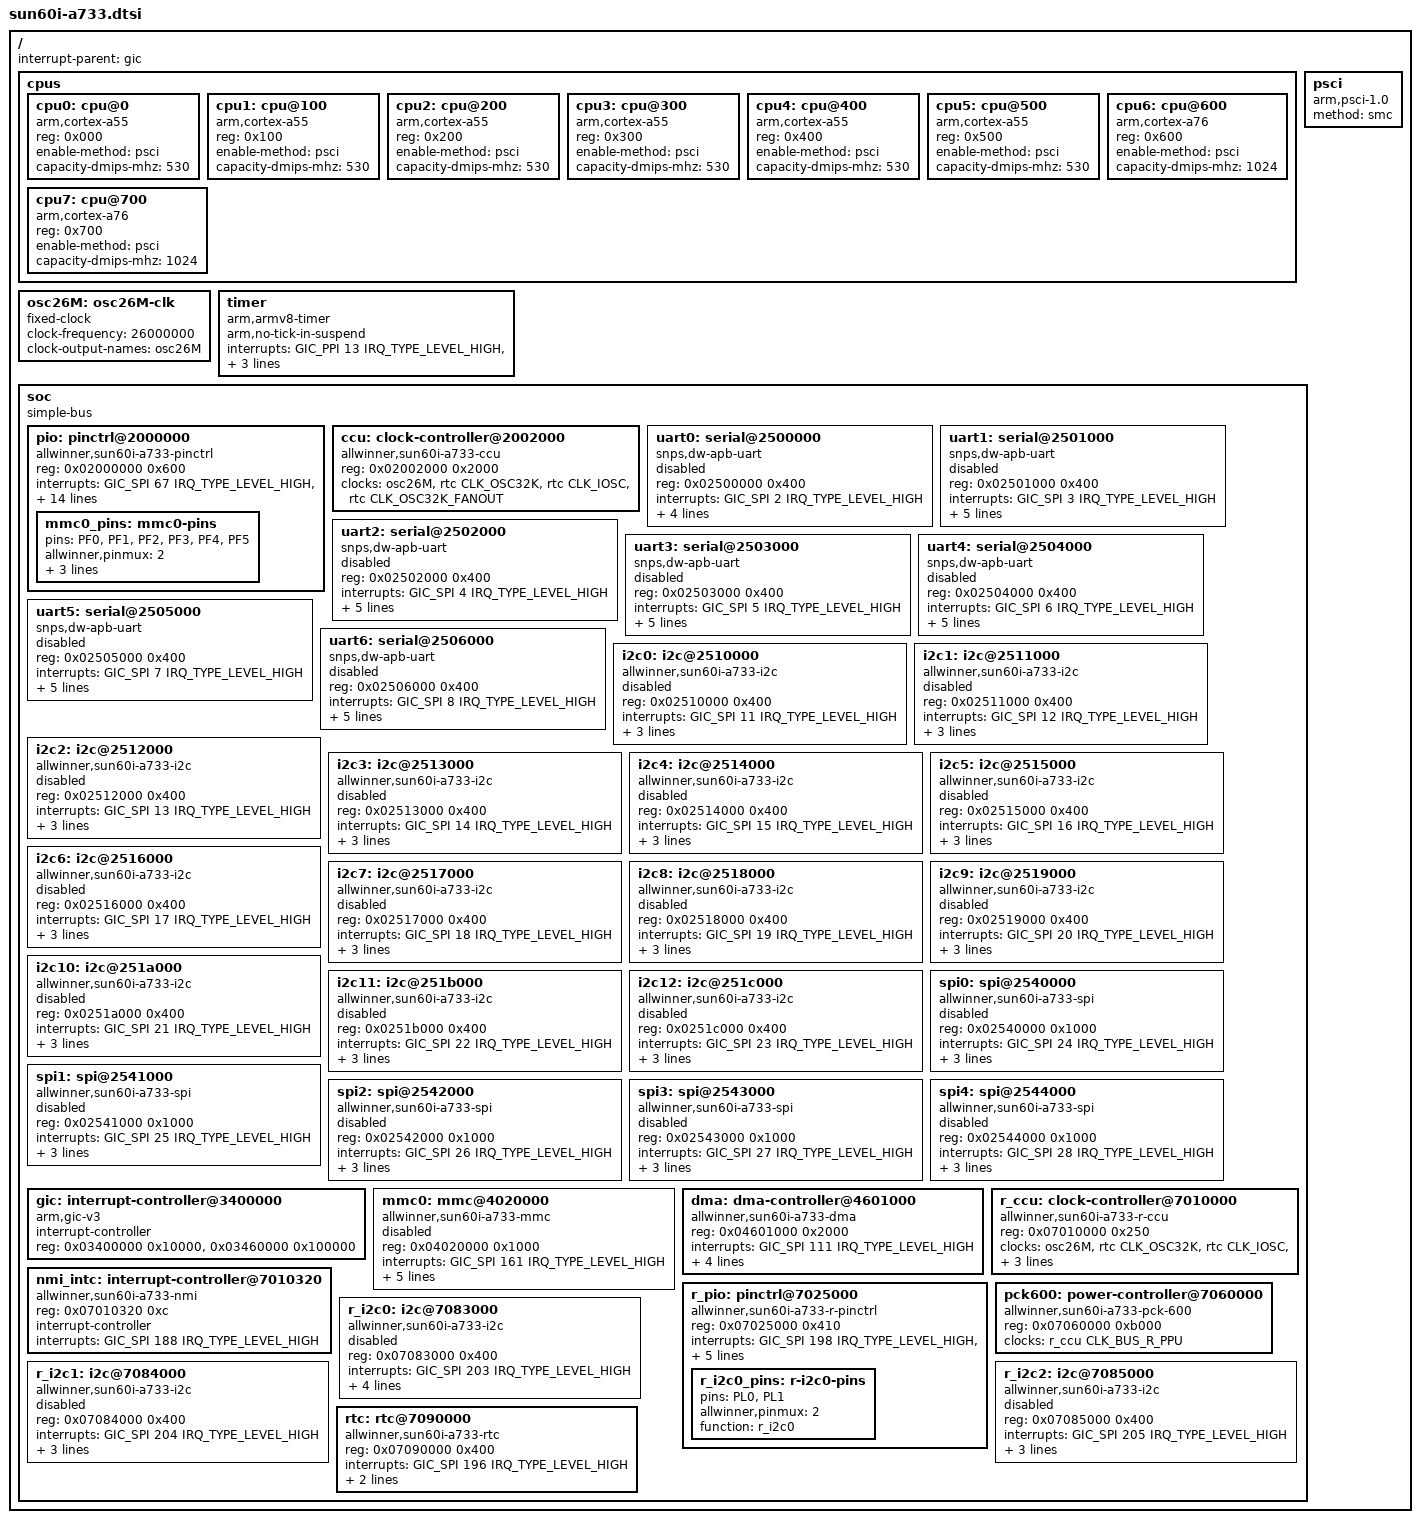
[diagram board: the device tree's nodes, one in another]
// SPDX-License-Identifier: (GPL-2.0-only OR MIT)

#include <dt-bindings/interrupt-controller/arm-gic.h>
#include <dt-bindings/clock/sun6i-rtc.h>
#include <dt-bindings/clock/sun60i-a733-ccu.h>
#include <dt-bindings/clock/sun60i-a733-r-ccu.h>
#include <dt-bindings/power/allwinner,sun60i-a733-pck-600.h>
#include <dt-bindings/reset/sun60i-a733-ccu.h>
#include <dt-bindings/reset/sun60i-a733-r-ccu.h>

/ {
	interrupt-parent = <&gic>;
	#address-cells = <2>;
	#size-cells = <2>;

	cpus {
		#address-cells = <1>;
		#size-cells = <0>;

		cpu0: cpu@0 {
			compatible = "arm,cortex-a55";
			device_type = "cpu";
			reg = <0x000>;
			enable-method = "psci";
			capacity-dmips-mhz = <530>;
		};

		cpu1: cpu@100 {
			compatible = "arm,cortex-a55";
			device_type = "cpu";
			reg = <0x100>;
			enable-method = "psci";
			capacity-dmips-mhz = <530>;
		};

		cpu2: cpu@200 {
			compatible = "arm,cortex-a55";
			device_type = "cpu";
			reg = <0x200>;
			enable-method = "psci";
			capacity-dmips-mhz = <530>;
		};

		cpu3: cpu@300 {
			compatible = "arm,cortex-a55";
			device_type = "cpu";
			reg = <0x300>;
			enable-method = "psci";
			capacity-dmips-mhz = <530>;
		};

		cpu4: cpu@400 {
			compatible = "arm,cortex-a55";
			device_type = "cpu";
			reg = <0x400>;
			enable-method = "psci";
			capacity-dmips-mhz = <530>;
		};

		cpu5: cpu@500 {
			compatible = "arm,cortex-a55";
			device_type = "cpu";
			reg = <0x500>;
			enable-method = "psci";
			capacity-dmips-mhz = <530>;
		};

		cpu6: cpu@600 {
			compatible = "arm,cortex-a76";
			device_type = "cpu";
			reg = <0x600>;
			enable-method = "psci";
			capacity-dmips-mhz = <1024>;
		};

		cpu7: cpu@700 {
			compatible = "arm,cortex-a76";
			device_type = "cpu";
			reg = <0x700>;
			enable-method = "psci";
			capacity-dmips-mhz = <1024>;
		};
	};

	osc26M: osc26M-clk {
		#clock-cells = <0>;
		compatible = "fixed-clock";
		clock-frequency = <26000000>;
		clock-output-names = "osc26M";
	};

	psci {
		compatible = "arm,psci-1.0", "arm,psci-0.2";
		method = "smc";
	};

	timer {
		compatible = "arm,armv8-timer";
		arm,no-tick-in-suspend;
		interrupts = <GIC_PPI 13 IRQ_TYPE_LEVEL_HIGH>,
			     <GIC_PPI 14 IRQ_TYPE_LEVEL_HIGH>,
			     <GIC_PPI 11 IRQ_TYPE_LEVEL_HIGH>,
			     <GIC_PPI 10 IRQ_TYPE_LEVEL_HIGH>;
	};

	soc {
		compatible = "simple-bus";
		#address-cells = <1>;
		#size-cells = <1>;
		ranges = <0x0 0x0 0x0 0x40000000>;

		pio: pinctrl@2000000 {
			compatible = "allwinner,sun60i-a733-pinctrl";
			reg = <0x02000000 0x600>;
			interrupts = <GIC_SPI 67 IRQ_TYPE_LEVEL_HIGH>,
				     <GIC_SPI 69 IRQ_TYPE_LEVEL_HIGH>,
				     <GIC_SPI 71 IRQ_TYPE_LEVEL_HIGH>,
				     <GIC_SPI 73 IRQ_TYPE_LEVEL_HIGH>,
				     <GIC_SPI 75 IRQ_TYPE_LEVEL_HIGH>,
				     <GIC_SPI 77 IRQ_TYPE_LEVEL_HIGH>,
				     <GIC_SPI 79 IRQ_TYPE_LEVEL_HIGH>,
				     <GIC_SPI 81 IRQ_TYPE_LEVEL_HIGH>,
				     <GIC_SPI 83 IRQ_TYPE_LEVEL_HIGH>,
				     <GIC_SPI 85 IRQ_TYPE_LEVEL_HIGH>,
				     <GIC_SPI 87 IRQ_TYPE_LEVEL_HIGH>;
			clocks = <&ccu CLK_APB1>, <&ccu CLK_SYS_24M>,
				 <&rtc CLK_OSC32K>;
			clock-names = "apb", "hosc", "losc";
			gpio-controller;
			#gpio-cells = <3>;
			interrupt-controller;
			#interrupt-cells = <3>;

			mmc0_pins: mmc0-pins {
				pins = "PF0", "PF1", "PF2",
				       "PF3", "PF4", "PF5";
				allwinner,pinmux = <2>;
				function = "mmc0";
				drive-strength = <30>;
				bias-pull-up;
			};

		};

		ccu: clock-controller@2002000 {
			compatible = "allwinner,sun60i-a733-ccu";
			reg = <0x02002000 0x2000>;
			clocks = <&osc26M>, <&rtc CLK_OSC32K>,
				 <&rtc CLK_IOSC>, <&rtc CLK_OSC32K_FANOUT>;
			clock-names = "hosc", "losc",
				      "iosc", "losc-fanout";
			#clock-cells = <1>;
			#reset-cells = <1>;
		};

		uart0: serial@2500000 {
			compatible = "snps,dw-apb-uart";
			reg = <0x02500000 0x400>;
			interrupts = <GIC_SPI 2 IRQ_TYPE_LEVEL_HIGH>;
			reg-shift = <2>;
			reg-io-width = <4>;
			clocks = <&ccu CLK_BUS_UART0>;
			resets = <&ccu RST_BUS_UART0>;
			status = "disabled";
		};

		uart1: serial@2501000 {
			compatible = "snps,dw-apb-uart";
			reg = <0x02501000 0x400>;
			interrupts = <GIC_SPI 3 IRQ_TYPE_LEVEL_HIGH>;
			reg-shift = <2>;
			reg-io-width = <4>;
			clocks = <&ccu CLK_BUS_UART1>;
			resets = <&ccu RST_BUS_UART1>;
			dmas = <&dma 15>, <&dma 15>;
			dma-names = "tx", "rx";
			status = "disabled";
		};

		uart2: serial@2502000 {
			compatible = "snps,dw-apb-uart";
			reg = <0x02502000 0x400>;
			interrupts = <GIC_SPI 4 IRQ_TYPE_LEVEL_HIGH>;
			reg-shift = <2>;
			reg-io-width = <4>;
			clocks = <&ccu CLK_BUS_UART2>;
			resets = <&ccu RST_BUS_UART2>;
			dmas = <&dma 16>, <&dma 16>;
			dma-names = "tx", "rx";
			status = "disabled";
		};

		uart3: serial@2503000 {
			compatible = "snps,dw-apb-uart";
			reg = <0x02503000 0x400>;
			interrupts = <GIC_SPI 5 IRQ_TYPE_LEVEL_HIGH>;
			reg-shift = <2>;
			reg-io-width = <4>;
			clocks = <&ccu CLK_BUS_UART3>;
			resets = <&ccu RST_BUS_UART3>;
			dmas = <&dma 17>, <&dma 17>;
			dma-names = "tx", "rx";
			status = "disabled";
		};

		uart4: serial@2504000 {
			compatible = "snps,dw-apb-uart";
			reg = <0x02504000 0x400>;
			interrupts = <GIC_SPI 6 IRQ_TYPE_LEVEL_HIGH>;
			reg-shift = <2>;
			reg-io-width = <4>;
			clocks = <&ccu CLK_BUS_UART4>;
			resets = <&ccu RST_BUS_UART4>;
			dmas = <&dma 18>, <&dma 18>;
			dma-names = "tx", "rx";
			status = "disabled";
		};

		uart5: serial@2505000 {
			compatible = "snps,dw-apb-uart";
			reg = <0x02505000 0x400>;
			interrupts = <GIC_SPI 7 IRQ_TYPE_LEVEL_HIGH>;
			reg-shift = <2>;
			reg-io-width = <4>;
			clocks = <&ccu CLK_BUS_UART5>;
			resets = <&ccu RST_BUS_UART5>;
			dmas = <&dma 19>, <&dma 19>;
			dma-names = "tx", "rx";
			status = "disabled";
		};

		uart6: serial@2506000 {
			compatible = "snps,dw-apb-uart";
			reg = <0x02506000 0x400>;
			interrupts = <GIC_SPI 8 IRQ_TYPE_LEVEL_HIGH>;
			reg-shift = <2>;
			reg-io-width = <4>;
			clocks = <&ccu CLK_BUS_UART6>;
			resets = <&ccu RST_BUS_UART6>;
			dmas = <&dma 20>, <&dma 20>;
			dma-names = "tx", "rx";
			status = "disabled";
		};

		i2c0: i2c@2510000 {
			compatible = "allwinner,sun60i-a733-i2c",
				     "allwinner,sun8i-v536-i2c",
				     "allwinner,sun6i-a31-i2c";
			reg = <0x02510000 0x400>;
			interrupts = <GIC_SPI 11 IRQ_TYPE_LEVEL_HIGH>;
			clocks = <&ccu CLK_BUS_I2C0>;
			resets = <&ccu RST_BUS_I2C0>;
			dmas = <&dma 37>, <&dma 37>;
			dma-names = "rx", "tx";
			status = "disabled";
			#address-cells = <1>;
			#size-cells = <0>;
		};

		i2c1: i2c@2511000 {
			compatible = "allwinner,sun60i-a733-i2c",
				     "allwinner,sun8i-v536-i2c",
				     "allwinner,sun6i-a31-i2c";
			reg = <0x02511000 0x400>;
			interrupts = <GIC_SPI 12 IRQ_TYPE_LEVEL_HIGH>;
			clocks = <&ccu CLK_BUS_I2C1>;
			resets = <&ccu RST_BUS_I2C1>;
			dmas = <&dma 38>, <&dma 38>;
			dma-names = "rx", "tx";
			status = "disabled";
			#address-cells = <1>;
			#size-cells = <0>;
		};

		i2c2: i2c@2512000 {
			compatible = "allwinner,sun60i-a733-i2c",
				     "allwinner,sun8i-v536-i2c",
				     "allwinner,sun6i-a31-i2c";
			reg = <0x02512000 0x400>;
			interrupts = <GIC_SPI 13 IRQ_TYPE_LEVEL_HIGH>;
			clocks = <&ccu CLK_BUS_I2C2>;
			resets = <&ccu RST_BUS_I2C2>;
			dmas = <&dma 39>, <&dma 39>;
			dma-names = "rx", "tx";
			status = "disabled";
			#address-cells = <1>;
			#size-cells = <0>;
		};

		i2c3: i2c@2513000 {
			compatible = "allwinner,sun60i-a733-i2c",
				     "allwinner,sun8i-v536-i2c",
				     "allwinner,sun6i-a31-i2c";
			reg = <0x02513000 0x400>;
			interrupts = <GIC_SPI 14 IRQ_TYPE_LEVEL_HIGH>;
			clocks = <&ccu CLK_BUS_I2C3>;
			resets = <&ccu RST_BUS_I2C3>;
			dmas = <&dma 40>, <&dma 40>;
			dma-names = "rx", "tx";
			status = "disabled";
			#address-cells = <1>;
			#size-cells = <0>;
		};

		i2c4: i2c@2514000 {
			compatible = "allwinner,sun60i-a733-i2c",
				     "allwinner,sun8i-v536-i2c",
				     "allwinner,sun6i-a31-i2c";
			reg = <0x02514000 0x400>;
			interrupts = <GIC_SPI 15 IRQ_TYPE_LEVEL_HIGH>;
			clocks = <&ccu CLK_BUS_I2C4>;
			resets = <&ccu RST_BUS_I2C4>;
			dmas = <&dma 41>, <&dma 41>;
			dma-names = "rx", "tx";
			status = "disabled";
			#address-cells = <1>;
			#size-cells = <0>;
		};

		i2c5: i2c@2515000 {
			compatible = "allwinner,sun60i-a733-i2c",
				     "allwinner,sun8i-v536-i2c",
				     "allwinner,sun6i-a31-i2c";
			reg = <0x02515000 0x400>;
			interrupts = <GIC_SPI 16 IRQ_TYPE_LEVEL_HIGH>;
			clocks = <&ccu CLK_BUS_I2C5>;
			resets = <&ccu RST_BUS_I2C5>;
			dmas = <&dma 42>, <&dma 42>;
			dma-names = "rx", "tx";
			status = "disabled";
			#address-cells = <1>;
			#size-cells = <0>;
		};

		i2c6: i2c@2516000 {
			compatible = "allwinner,sun60i-a733-i2c",
				     "allwinner,sun8i-v536-i2c",
				     "allwinner,sun6i-a31-i2c";
			reg = <0x02516000 0x400>;
			interrupts = <GIC_SPI 17 IRQ_TYPE_LEVEL_HIGH>;
			clocks = <&ccu CLK_BUS_I2C6>;
			resets = <&ccu RST_BUS_I2C6>;
			dmas = <&dma 43>, <&dma 43>;
			dma-names = "rx", "tx";
			status = "disabled";
			#address-cells = <1>;
			#size-cells = <0>;
		};

		i2c7: i2c@2517000 {
			compatible = "allwinner,sun60i-a733-i2c",
				     "allwinner,sun8i-v536-i2c",
				     "allwinner,sun6i-a31-i2c";
			reg = <0x02517000 0x400>;
			interrupts = <GIC_SPI 18 IRQ_TYPE_LEVEL_HIGH>;
			clocks = <&ccu CLK_BUS_I2C7>;
			resets = <&ccu RST_BUS_I2C7>;
			dmas = <&dma 44>, <&dma 44>;
			dma-names = "rx", "tx";
			status = "disabled";
			#address-cells = <1>;
			#size-cells = <0>;
		};

		i2c8: i2c@2518000 {
			compatible = "allwinner,sun60i-a733-i2c",
				     "allwinner,sun8i-v536-i2c",
				     "allwinner,sun6i-a31-i2c";
			reg = <0x02518000 0x400>;
			interrupts = <GIC_SPI 19 IRQ_TYPE_LEVEL_HIGH>;
			clocks = <&ccu CLK_BUS_I2C8>;
			resets = <&ccu RST_BUS_I2C8>;
			dmas = <&dma 45>, <&dma 45>;
			dma-names = "rx", "tx";
			status = "disabled";
			#address-cells = <1>;
			#size-cells = <0>;
		};

		i2c9: i2c@2519000 {
			compatible = "allwinner,sun60i-a733-i2c",
				     "allwinner,sun8i-v536-i2c",
				     "allwinner,sun6i-a31-i2c";
			reg = <0x02519000 0x400>;
			interrupts = <GIC_SPI 20 IRQ_TYPE_LEVEL_HIGH>;
			clocks = <&ccu CLK_BUS_I2C9>;
			resets = <&ccu RST_BUS_I2C9>;
			dmas = <&dma 58>, <&dma 58>;
			dma-names = "rx", "tx";
			status = "disabled";
			#address-cells = <1>;
			#size-cells = <0>;
		};

		i2c10: i2c@251a000 {
			compatible = "allwinner,sun60i-a733-i2c",
				     "allwinner,sun8i-v536-i2c",
				     "allwinner,sun6i-a31-i2c";
			reg = <0x0251a000 0x400>;
			interrupts = <GIC_SPI 21 IRQ_TYPE_LEVEL_HIGH>;
			clocks = <&ccu CLK_BUS_I2C10>;
			resets = <&ccu RST_BUS_I2C10>;
			dmas = <&dma 59>, <&dma 59>;
			dma-names = "rx", "tx";
			status = "disabled";
			#address-cells = <1>;
			#size-cells = <0>;
		};

		i2c11: i2c@251b000 {
			compatible = "allwinner,sun60i-a733-i2c",
				     "allwinner,sun8i-v536-i2c",
				     "allwinner,sun6i-a31-i2c";
			reg = <0x0251b000 0x400>;
			interrupts = <GIC_SPI 22 IRQ_TYPE_LEVEL_HIGH>;
			clocks = <&ccu CLK_BUS_I2C11>;
			resets = <&ccu RST_BUS_I2C11>;
			dmas = <&dma 60>, <&dma 60>;
			dma-names = "rx", "tx";
			status = "disabled";
			#address-cells = <1>;
			#size-cells = <0>;
		};

		i2c12: i2c@251c000 {
			compatible = "allwinner,sun60i-a733-i2c",
				     "allwinner,sun8i-v536-i2c",
				     "allwinner,sun6i-a31-i2c";
			reg = <0x0251c000 0x400>;
			interrupts = <GIC_SPI 23 IRQ_TYPE_LEVEL_HIGH>;
			clocks = <&ccu CLK_BUS_I2C12>;
			resets = <&ccu RST_BUS_I2C12>;
			dmas = <&dma 61>, <&dma 61>;
			dma-names = "rx", "tx";
			status = "disabled";
			#address-cells = <1>;
			#size-cells = <0>;
		};

		spi0: spi@2540000 {
			compatible = "allwinner,sun60i-a733-spi",
				     "allwinner,sun55i-a523-spi";
			reg = <0x02540000 0x1000>;
			interrupts = <GIC_SPI 24 IRQ_TYPE_LEVEL_HIGH>;
			clocks = <&ccu CLK_BUS_SPI0>, <&ccu CLK_SPI0>;
			clock-names = "ahb", "mod";
			dmas = <&dma 23>, <&dma 23>;
			dma-names = "rx", "tx";
			resets = <&ccu RST_BUS_SPI0>;
			status = "disabled";
			#address-cells = <1>;
			#size-cells = <0>;
		};

		spi1: spi@2541000 {
			compatible = "allwinner,sun60i-a733-spi",
				     "allwinner,sun55i-a523-spi";
			reg = <0x02541000 0x1000>;
			interrupts = <GIC_SPI 25 IRQ_TYPE_LEVEL_HIGH>;
			clocks = <&ccu CLK_BUS_SPI1>, <&ccu CLK_SPI1>;
			clock-names = "ahb", "mod";
			dmas = <&dma 24>, <&dma 24>;
			dma-names = "rx", "tx";
			resets = <&ccu RST_BUS_SPI1>;
			status = "disabled";
			#address-cells = <1>;
			#size-cells = <0>;
		};

		spi2: spi@2542000 {
			compatible = "allwinner,sun60i-a733-spi",
				     "allwinner,sun55i-a523-spi";
			reg = <0x02542000 0x1000>;
			interrupts = <GIC_SPI 26 IRQ_TYPE_LEVEL_HIGH>;
			clocks = <&ccu CLK_BUS_SPI2>, <&ccu CLK_SPI2>;
			clock-names = "ahb", "mod";
			dmas = <&dma 25>, <&dma 25>;
			dma-names = "rx", "tx";
			resets = <&ccu RST_BUS_SPI2>;
			status = "disabled";
			#address-cells = <1>;
			#size-cells = <0>;
		};

		spi3: spi@2543000 {
			compatible = "allwinner,sun60i-a733-spi",
				     "allwinner,sun55i-a523-spi";
			reg = <0x02543000 0x1000>;
			interrupts = <GIC_SPI 27 IRQ_TYPE_LEVEL_HIGH>;
			clocks = <&ccu CLK_BUS_SPI3>, <&ccu CLK_SPI3>;
			clock-names = "ahb", "mod";
			dmas = <&dma 26>, <&dma 26>;
			dma-names = "rx", "tx";
			resets = <&ccu RST_BUS_SPI3>;
			status = "disabled";
			#address-cells = <1>;
			#size-cells = <0>;
		};

		spi4: spi@2544000 {
			compatible = "allwinner,sun60i-a733-spi",
				     "allwinner,sun55i-a523-spi";
			reg = <0x02544000 0x1000>;
			interrupts = <GIC_SPI 28 IRQ_TYPE_LEVEL_HIGH>;
			clocks = <&ccu CLK_BUS_SPI4>, <&ccu CLK_SPI4>;
			clock-names = "ahb", "mod";
			dmas = <&dma 54>, <&dma 54>;
			dma-names = "rx", "tx";
			resets = <&ccu RST_BUS_SPI4>;
			status = "disabled";
			#address-cells = <1>;
			#size-cells = <0>;
		};

		gic: interrupt-controller@3400000 {
			compatible = "arm,gic-v3";
			#interrupt-cells = <3>;
			interrupt-controller;
			reg = <0x03400000 0x10000>,
			      <0x03460000 0x100000>;
		};

		mmc0: mmc@4020000 {
			compatible = "allwinner,sun60i-a733-mmc",
				     "allwinner,sun20i-d1-mmc";
			reg = <0x04020000 0x1000>;
			interrupts = <GIC_SPI 161 IRQ_TYPE_LEVEL_HIGH>;
			clocks = <&ccu CLK_BUS_MMC0>, <&ccu CLK_MMC0>;
			clock-names = "ahb", "mmc";
			resets = <&ccu RST_BUS_MMC0>;
			reset-names = "ahb";
			pinctrl-names = "default";
			pinctrl-0 = <&mmc0_pins>;
			max-frequency = <200000000>;
			cap-sd-highspeed;
			status = "disabled";
			#address-cells = <1>;
			#size-cells = <0>;
		};

		dma: dma-controller@4601000 {
			compatible = "allwinner,sun60i-a733-dma";
			reg = <0x04601000 0x2000>;
			interrupts = <GIC_SPI 111 IRQ_TYPE_LEVEL_HIGH>;
			clocks = <&ccu CLK_BUS_DMA0>, <&ccu CLK_MBUS_DMA0>;
			clock-names = "bus", "mbus";
			dma-channels = <16>;
			dma-requests = <64>;
			resets = <&ccu RST_BUS_DMA0>;
			#dma-cells = <1>;
		};

		r_ccu: clock-controller@7010000 {
			compatible = "allwinner,sun60i-a733-r-ccu";
			reg = <0x07010000 0x250>;
			clocks = <&osc26M>,
				 <&rtc CLK_OSC32K>,
				 <&rtc CLK_IOSC>,
				 <&ccu CLK_SYS_24M>,
				 <&ccu CLK_PLL_PERIPH0_200M>,
				 <&ccu CLK_PLL_PERIPH0_300M>,
				 <&ccu CLK_PLL_PERIPH1_300M>;
			clock-names = "hosc",
				      "losc",
				      "iosc",
				      "sys-24m",
				      "pll-periph0-200m",
				      "pll-periph0-300m",
				      "pll-periph1-300m";
			#clock-cells = <1>;
			#reset-cells = <1>;
		};

		nmi_intc: interrupt-controller@7010320 {
			compatible = "allwinner,sun60i-a733-nmi",
				     "allwinner,sun55i-a523-nmi";
			reg = <0x07010320 0xc>;
			interrupt-controller;
			#interrupt-cells = <2>;
			interrupts = <GIC_SPI 188 IRQ_TYPE_LEVEL_HIGH>;
		};

		r_pio: pinctrl@7025000 {
			compatible = "allwinner,sun60i-a733-r-pinctrl";
			reg = <0x07025000 0x410>;
			interrupts = <GIC_SPI 198 IRQ_TYPE_LEVEL_HIGH>,
				     <GIC_SPI 200 IRQ_TYPE_LEVEL_HIGH>;
			clocks = <&r_ccu CLK_R_APB0>,
				 <&osc26M>,
				 <&rtc CLK_OSC32K>;
			clock-names = "apb", "hosc", "losc";
			gpio-controller;
			#gpio-cells = <3>;
			interrupt-controller;
			#interrupt-cells = <3>;

			r_i2c0_pins: r-i2c0-pins {
				pins = "PL0", "PL1";
				allwinner,pinmux = <2>;
				function = "r_i2c0";
			};
		};

		pck600: power-controller@7060000 {
			compatible = "allwinner,sun60i-a733-pck-600";
			reg = <0x07060000 0xb000>;
			clocks = <&r_ccu CLK_BUS_R_PPU>;
			#power-domain-cells = <1>;
		};

		r_i2c0: i2c@7083000 {
			compatible = "allwinner,sun60i-a733-i2c",
				     "allwinner,sun8i-v536-i2c",
				     "allwinner,sun6i-a31-i2c";
			reg = <0x07083000 0x400>;
			interrupts = <GIC_SPI 203 IRQ_TYPE_LEVEL_HIGH>;
			clocks = <&r_ccu CLK_BUS_R_I2C0>;
			resets = <&r_ccu RST_BUS_R_I2C0>;
			dmas = <&dma 47>, <&dma 47>;
			dma-names = "rx", "tx";
			pinctrl-names = "default";
			pinctrl-0 = <&r_i2c0_pins>;
			status = "disabled";
			#address-cells = <1>;
			#size-cells = <0>;
		};

		r_i2c1: i2c@7084000 {
			compatible = "allwinner,sun60i-a733-i2c",
				     "allwinner,sun8i-v536-i2c",
				     "allwinner,sun6i-a31-i2c";
			reg = <0x07084000 0x400>;
			interrupts = <GIC_SPI 204 IRQ_TYPE_LEVEL_HIGH>;
			clocks = <&r_ccu CLK_BUS_R_I2C1>;
			resets = <&r_ccu RST_BUS_R_I2C1>;
			dmas = <&dma 48>, <&dma 48>;
			dma-names = "rx", "tx";
			status = "disabled";
			#address-cells = <1>;
			#size-cells = <0>;
		};

		r_i2c2: i2c@7085000 {
			compatible = "allwinner,sun60i-a733-i2c",
				     "allwinner,sun8i-v536-i2c",
				     "allwinner,sun6i-a31-i2c";
			reg = <0x07085000 0x400>;
			interrupts = <GIC_SPI 205 IRQ_TYPE_LEVEL_HIGH>;
			clocks = <&r_ccu CLK_BUS_R_I2C2>;
			resets = <&r_ccu RST_BUS_R_I2C2>;
			dmas = <&dma 49>, <&dma 49>;
			dma-names = "rx", "tx";
			status = "disabled";
			#address-cells = <1>;
			#size-cells = <0>;
		};

		rtc: rtc@7090000 {
			compatible = "allwinner,sun60i-a733-rtc",
				     "allwinner,sun50i-r329-rtc";
			reg = <0x07090000 0x400>;
			interrupts = <GIC_SPI 196 IRQ_TYPE_LEVEL_HIGH>;
			clocks = <&r_ccu CLK_BUS_R_RTC>,
				 <&osc26M>,
				 <&r_ccu CLK_R_AHB>;
			clock-names = "bus", "hosc", "ahb";
			#clock-cells = <1>;
		};
	};
};
